AUTOSAR XML (schema 4-2-2)
# \copyright BMW AG 2014 - 2017
package /BMW/Platform/Omc/SwcImplementations
  swc implementation Omc_Implementation: programming-language=C, sw-version=5.2.0, vendor-id=5, behavior=InternalBehavior
    code-descriptors:
      code Code1: artifact-descriptors=autosar-engineering-object={short-label=dummy, category=dummy}
    resource consumption dummy
package /BMW/Platform/Omc/SwComponentTypes
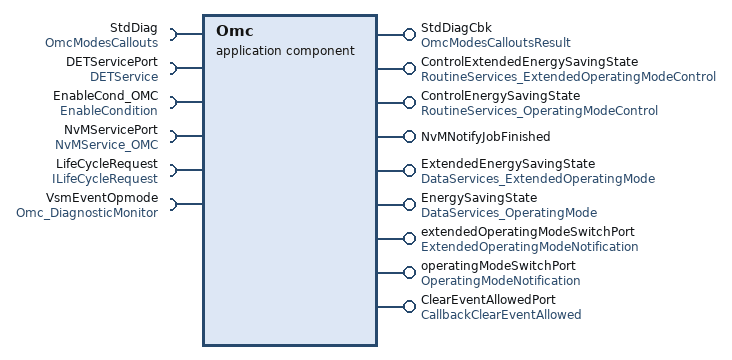
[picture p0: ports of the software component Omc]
  application sw component type Omc
    require port StdDiag: required-interface=OmcModesCallouts
    provide port StdDiagCbk: provided-interface=OmcModesCalloutsResult
    provide port ControlExtendedEnergySavingState: provided-interface=RoutineServices_ExtendedOperatingModeControl
    provide port ControlEnergySavingState: provided-interface=RoutineServices_OperatingModeControl
    require port DETServicePort: required-interface=DETService
    require port EnableCond_OMC: required-interface=EnableCondition
    require port NvMServicePort: required-interface=NvMService_OMC
    5 x provide port:
      NvMNotifyJobFinished: server-com-spec{operation=JobFinished, queue-length=1}, provided-interface=NvMNotifyJobFinished
      ExtendedEnergySavingState: provided-interface=DataServices_ExtendedOperatingMode
      EnergySavingState: provided-interface=DataServices_OperatingMode
      extendedOperatingModeSwitchPort: provided-interface=ExtendedOperatingModeNotification
      operatingModeSwitchPort: provided-interface=OperatingModeNotification
    require port LifeCycleRequest: nonqueued-receiver-com-spec{data-element=requestMode, init-value=2}, required-interface=ILifeCycleRequest
    provide/require port LifeCycle: mode-switch-sender-com-spec{enhanced-mode-api=true, mode-group=Mode, queue-length=2}, provided-required-interface=ILifeCycle
    require port VsmEventOpmode: required-interface=Omc_DiagnosticMonitor
    provide port ClearEventAllowedPort: provided-interface=CallbackClearEventAllowed
    behavior InternalBehavior: data-type-mapping=Omc_DataTypeMappingSets, handle-termination-and-restart=NO-SUPPORT, included-data-type-set=data-type=[Omc_ExtendedOperatingModeType, Omc_OperatingModeType]
      exclusive area Mode
      9 x operation invoked event:
        E_StdDiag_OpModeSwitchAllowedResult: start-on-event=StdDiag_OpModeSwitchAllowedResult, operation=StdDiagCbk.OpModeSwitchAllowedResult
        E_StdDiag_OpModeSwitchCancelledAck: start-on-event=StdDiag_OpModeSwitchCancelledAck, operation=StdDiagCbk.OpModeSwitchCancelledAck
        E_ChangeExtendedOperatingMode: start-on-event=ChangeExtendedOperatingMode, operation=ControlExtendedEnergySavingState.Start
        E_ChangeOperatingMode: start-on-event=ChangeOperatingMode, operation=ControlEnergySavingState.Start
        E_ConditionCheckReadExtendedOperatingMode: start-on-event=ConditionCheckReadExtendedOperatingMode, operation=ExtendedEnergySavingState.ConditionCheckRead
        E_NvMNotifyJobFinished: start-on-event=NvMWriteJobFinished, operation=NvMNotifyJobFinished.JobFinished
        E_ReadDIDExtendedOperatingMode: start-on-event=ReadDIDExtendedOperatingMode, operation=ExtendedEnergySavingState.ReadData
        E_ReadOperatingMode: start-on-event=ReadOperatingMode, operation=EnergySavingState.ReadData
        E_ConditionCheckReadDIDOperatingMode: start-on-event=ConditionCheckReadOperatingMode, operation=EnergySavingState.ConditionCheckRead
      data received event LifeCycleRequest: start-on-event=LifeCycleHandler, data=LifeCycleRequest.requestMode
      operation invoked event E_ClearEventAllowed: start-on-event=ClearEventAllowed, operation=ClearEventAllowedPort.ClearEventAllowed
      11 x runnable:
        ChangeExtendedOperatingMode: can-enter-exclusive-area=Mode, can-be-invoked-concurrently=true, symbol=Omc_RoutineControlStartExtendedOperatingMode
          5 x sync call, all with timeout=0.0:
            SSCP_WriteBlock: operation=NvMServicePort.WriteBlock
            SSCP_GetErrorStatus: operation=NvMServicePort.GetErrorStatus
            SSCP_OmcStdDiagOpModeCallout: operation=StdDiag.AllowOpModeSwitch
            SSCP_OmcStdDiagOpModeCancelledCallout: operation=StdDiag.OpModeSwitchCancelled
            SSCP_ReportError: operation=DETServicePort.ReportError
        ChangeOperatingMode: can-enter-exclusive-area=Mode, can-be-invoked-concurrently=true, symbol=Omc_RoutineControlStartOperatingMode
          5 x sync call, all with timeout=0.0:
            SSCP_WriteBlock: operation=NvMServicePort.WriteBlock
            SSCP_GetErrorStatus: operation=NvMServicePort.GetErrorStatus
            SSCP_ReportError: operation=DETServicePort.ReportError
            SSCP_OmcStdDiagOpModeCallout: operation=StdDiag.AllowOpModeSwitch
            SSCP_OmcStdDiagOpModeCancelledCallout: operation=StdDiag.OpModeSwitchCancelled
        ConditionCheckReadExtendedOperatingMode: can-enter-exclusive-area=Mode, can-be-invoked-concurrently=true, symbol=Omc_ConditionCheckReadDIDExtendedOperatingMode
          sync call SSCP_ReportError: operation=DETServicePort.ReportError, timeout=0.0
        ConditionCheckReadOperatingMode: can-enter-exclusive-area=Mode, can-be-invoked-concurrently=true, symbol=Omc_ConditionCheckReadDIDOperatingMode
          sync call SSCP_ReportError: operation=DETServicePort.ReportError, timeout=0.0
        LifeCycleHandler: can-enter-exclusive-area=Mode, mode-access-point=LifeCycle.Mode, symbol=Omc_LifeCycleHandler
          data-read-access:
            access requestedMode: accessed-variable=LifeCycleRequest.requestMode
          mode switch point LifeCycle: mode-group=LifeCycle.Mode
          mode switch point MSP_currentOperatingMode: mode-group=operatingModeSwitchPort.currentOperatingMode
          mode switch point MSP_currentExtendedOperatingMode: mode-group=extendedOperatingModeSwitchPort.currentExtendedOperatingMode
          sync call SSCP_SetEnableCondition: operation=EnableCond_OMC.SetEnableCondition, timeout=0.0
          sync call SSCP_SetEventStatus: operation=VsmEventOpmode.SetEventStatus, timeout=0.0
          sync call SSCP_ReportError: operation=DETServicePort.ReportError, timeout=0.0
        ReadDIDExtendedOperatingMode: can-enter-exclusive-area=Mode, can-be-invoked-concurrently=true, symbol=Omc_ReadDIDExtendedOperatingMode
          sync call SSCP_ReportError: operation=DETServicePort.ReportError, timeout=0.0
        ReadOperatingMode: can-enter-exclusive-area=Mode, can-be-invoked-concurrently=true, symbol=Omc_ReadDIDOperatingMode
          sync call SSCP_ReportError: operation=DETServicePort.ReportError, timeout=0.0
        NvMWriteJobFinished: can-enter-exclusive-area=Mode, can-be-invoked-concurrently=true, symbol=Omc_NvMNotifyJobFinishedOperatingModes
          mode switch point MSP_currentOperatingMode: mode-group=operatingModeSwitchPort.currentOperatingMode
          mode switch point MSP_currentExtendedOperatingMode: mode-group=extendedOperatingModeSwitchPort.currentExtendedOperatingMode
          5 x sync call, all with timeout=0.0:
            SSCP_WriteBlock: operation=NvMServicePort.WriteBlock
            SSCP_GetErrorStatus: operation=NvMServicePort.GetErrorStatus
            SSCP_SetEnableCondition: operation=EnableCond_OMC.SetEnableCondition
            SSCP_SetEventStatus: operation=VsmEventOpmode.SetEventStatus
            SSCP_ReportError: operation=DETServicePort.ReportError
        ClearEventAllowed: can-enter-exclusive-area=Mode, can-be-invoked-concurrently=true, symbol=Omc_ClearEventAllowed
          sync call SSCP_ReportError: operation=DETServicePort.ReportError, timeout=0.0
        StdDiag_OpModeSwitchAllowedResult: can-be-invoked-concurrently=true, symbol=Omc_StdDiag_OpModeSwitchAllowedResult
        StdDiag_OpModeSwitchCancelledAck: can-be-invoked-concurrently=true, symbol=Omc_StdDiag_OpModeSwitchCancelledAck
      swc service dependency OmcDependencyNVMData: assigned-ports=role-based-port-assignment={port-prototype=NvMServicePort, role=NvmService}
        service-needs:
          nv block needs OmcNvBlockNeeds_Data: calc-ram-block-crc=false, n-data-sets=1, n-rom-blocks=1, restore-at-start=true, store-at-shutdown=false
